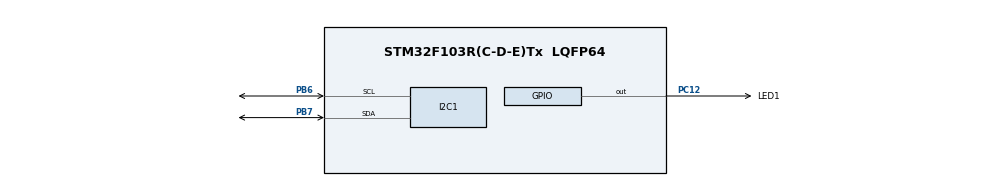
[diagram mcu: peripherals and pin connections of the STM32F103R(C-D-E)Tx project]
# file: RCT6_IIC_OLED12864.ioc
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Mcu.Family=STM32F1
Mcu.Name=STM32F103R(C-D-E)Tx
Mcu.Package=LQFP64
NVIC.PriorityGroup=NVIC_PRIORITYGROUP_4
PB6.Mode=I2C
PB6.Signal=I2C1_SCL
PB7.Mode=I2C
PB7.Signal=I2C1_SDA
PC12.GPIO_Label=LED1
PC12.Signal=GPIO_Output
ProjectManager.HeapSize=0x200
ProjectManager.StackSize=0x400
ProjectManager.TargetToolchain=MDK-ARM V5.27
RCC.APB1Freq_Value=8000000
RCC.APB2Freq_Value=8000000
VP_SYS_VS_ND.Mode=No_Debug
board=custom

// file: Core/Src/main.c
/* USER CODE BEGIN Header */
/**
  ******************************************************************************
  * @file           : main.c
  * @brief          : Main program body
  ******************************************************************************
  * @attention
  *
  * <h2><center>&copy; Copyright (c) 2021 STMicroelectronics.
  * All rights reserved.</center></h2>
  *
  * This software component is licensed by ST under BSD 3-Clause license,
  * the "License"; You may not use this file except in compliance with the
  * License. You may obtain a copy of the License at:
  *                        opensource.org/licenses/BSD-3-Clause
  *
  ******************************************************************************
  */
/* USER CODE END Header */
#include "main.h"
#include "i2c.h"
#include "gpio.h"
#include "oled.h"

void SystemClock_Config(void);

/* USER CODE BEGIN 0 */
int fputc(int ch,FILE *f)
{
 uint8_t temp[1]={ch};
 HAL_UART_Transmit(&huart,temp,1,2);
}
/* USER CODE END 0 */

int main(void)
{

  /* MCU Configuration--------------------------------------------------------*/

  /* Reset of all peripherals, Initializes the Flash interface and the Systick. */
  HAL_Init();

  /* Configure the system clock */
  SystemClock_Config();

  /* Initialize all configured peripherals */
  MX_GPIO_Init();
  MX_I2C1_Init();
  OLED_Init();
  /* USER CODE BEGIN 2 */
	OLED_Clear();
  /* USER CODE END 2 */
  OLED_ShowString(0,2,"Hello New World");
	OLED_ShowString(0,4,"From Anjiapulu");
  /* Infinite loop */
  while (1)
  {
   HAL_GPIO_WritePin(LED1_GPIO_Port,LED1_Pin,GPIO_PIN_RESET);
  }
}

void SystemClock_Config(void)
{
  RCC_OscInitTypeDef RCC_OscInitStruct = {0};
  RCC_ClkInitTypeDef RCC_ClkInitStruct = {0};

  /** Initializes the RCC Oscillators according to the specified parameters
  * in the RCC_OscInitTypeDef structure.
  */
  RCC_OscInitStruct.OscillatorType = RCC_OSCILLATORTYPE_HSI;
  RCC_OscInitStruct.HSIState = RCC_HSI_ON;
  RCC_OscInitStruct.HSICalibrationValue = RCC_HSICALIBRATION_DEFAULT;
  RCC_OscInitStruct.PLL.PLLState = RCC_PLL_NONE;
  if (HAL_RCC_OscConfig(&RCC_OscInitStruct) != HAL_OK)
  {
    Error_Handler();
  }
  /** Initializes the CPU, AHB and APB buses clocks
  */
  RCC_ClkInitStruct.ClockType = RCC_CLOCKTYPE_HCLK|RCC_CLOCKTYPE_SYSCLK
                              |RCC_CLOCKTYPE_PCLK1|RCC_CLOCKTYPE_PCLK2;
  RCC_ClkInitStruct.SYSCLKSource = RCC_SYSCLKSOURCE_HSI;
  RCC_ClkInitStruct.AHBCLKDivider = RCC_SYSCLK_DIV1;
  RCC_ClkInitStruct.APB1CLKDivider = RCC_HCLK_DIV1;
  RCC_ClkInitStruct.APB2CLKDivider = RCC_HCLK_DIV1;

  if (HAL_RCC_ClockConfig(&RCC_ClkInitStruct, FLASH_LATENCY_0) != HAL_OK)
  {
    Error_Handler();
  }
}

void Error_Handler(void)
{
  __disable_irq();
  while (1)
  {
  }
}

/************************ (C) COPYRIGHT STMicroelectronics *****END OF FILE****/
